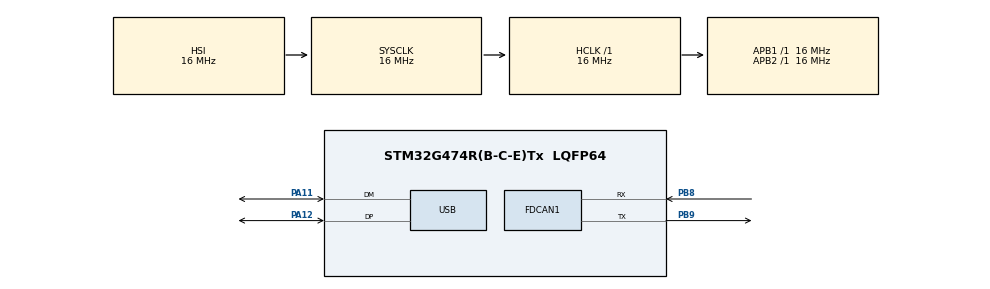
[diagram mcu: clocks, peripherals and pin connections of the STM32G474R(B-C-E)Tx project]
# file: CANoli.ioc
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FDCAN1.CalculateBaudRateNominal=333333
FDCAN1.CalculateTimeBitNominal=3000
FDCAN1.CalculateTimeQuantumNominal=1000.0
Mcu.Family=STM32G4
Mcu.Name=STM32G474R(B-C-E)Tx
Mcu.Package=LQFP64
NVIC.FDCAN1_IT0_IRQn=true\:0\:0\:false\:false\:true\:true\:true\:true
NVIC.FDCAN1_IT1_IRQn=true\:0\:0\:false\:false\:true\:true\:true\:true
NVIC.PriorityGroup=NVIC_PRIORITYGROUP_4
NVIC.USB_HP_IRQn=true\:0\:0\:false\:false\:true\:true\:true\:true
NVIC.USB_LP_IRQn=true\:0\:0\:false\:false\:true\:true\:true\:true
PA11.Mode=Device
PA11.Signal=USB_DM
PA12.Mode=Device
PA12.Signal=USB_DP
PB8-BOOT0.Mode=FDCAN_Activate
PB8-BOOT0.Signal=FDCAN1_RX
PB9.Mode=FDCAN_Activate
PB9.Signal=FDCAN1_TX
ProjectManager.HeapSize=0x200
ProjectManager.StackSize=0x400
ProjectManager.TargetToolchain=CMake
RCC.AHBFreq_Value=16000000
RCC.APB1Freq_Value=16000000
RCC.APB1TimFreq_Value=16000000
RCC.APB2Freq_Value=16000000
RCC.APB2TimFreq_Value=16000000
RCC.CortexFreq_Value=16000000
RCC.EXTERNAL_CLOCK_VALUE=12288000
RCC.HCLKFreq_Value=16000000
RCC.HSE_VALUE=8000000
RCC.HSI48_VALUE=48000000
RCC.HSI_VALUE=16000000
RCC.LSE_VALUE=32768
RCC.PLLN=12
RCC.PLLQ=RCC_PLLQ_DIV4
RCC.SYSCLKFreq_VALUE=16000000
RCC.USBFreq_Value=48000000
RCC.VCOOutputFreq_Value=192000000
VP_SYS_VS_DBSignals.Mode=DisableDeadBatterySignals
board=custom

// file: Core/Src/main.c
/* USER CODE BEGIN Header */
/**
  ******************************************************************************
  * @file           : main.c
  * @brief          : Main program body
  ******************************************************************************
  * @attention
  *
  * Copyright (c) 2026 STMicroelectronics.
  * All rights reserved.
  *
  * This software is licensed under terms that can be found in the LICENSE file
  * in the root directory of this software component.
  * If no LICENSE file comes with this software, it is provided AS-IS.
  *
  ******************************************************************************
  */
/* USER CODE END Header */
#include "main.h"

/* USER CODE BEGIN Includes */
#include "rosjam.h"
#include "tusb_config.h"
#include "tusb.h"

/* USER CODE END Includes */

FDCAN_HandleTypeDef hfdcan1;

PCD_HandleTypeDef hpcd_USB_FS;

void SystemClock_Config(void);
static void MX_GPIO_Init(void);
static void MX_FDCAN1_Init(void);
static void MX_USB_PCD_Init(void);

int main(void)
{

  /* MCU Configuration--------------------------------------------------------*/

  /* Reset of all peripherals, Initializes the Flash interface and the Systick. */
  HAL_Init();

  /* Configure the system clock */
  SystemClock_Config();

  /* Initialize all configured peripherals */
  MX_GPIO_Init();
  MX_FDCAN1_Init();
  MX_USB_PCD_Init();

  /* Infinite loop */
  /* USER CODE BEGIN WHILE */
  while (!tud_cdc_ready())
  {
    process_simple();
    /* USER CODE END WHILE */

  }
}

void SystemClock_Config(void)
{
  RCC_OscInitTypeDef RCC_OscInitStruct = {0};
  RCC_ClkInitTypeDef RCC_ClkInitStruct = {0};

  /** Configure the main internal regulator output voltage
  */
  HAL_PWREx_ControlVoltageScaling(PWR_REGULATOR_VOLTAGE_SCALE1);

  /** Initializes the RCC Oscillators according to the specified parameters
  * in the RCC_OscInitTypeDef structure.
  */
  RCC_OscInitStruct.OscillatorType = RCC_OSCILLATORTYPE_HSI;
  RCC_OscInitStruct.HSIState = RCC_HSI_ON;
  RCC_OscInitStruct.HSICalibrationValue = RCC_HSICALIBRATION_DEFAULT;
  RCC_OscInitStruct.PLL.PLLState = RCC_PLL_ON;
  RCC_OscInitStruct.PLL.PLLSource = RCC_PLLSOURCE_HSI;
  RCC_OscInitStruct.PLL.PLLM = RCC_PLLM_DIV1;
  RCC_OscInitStruct.PLL.PLLN = 12;
  RCC_OscInitStruct.PLL.PLLP = RCC_PLLP_DIV2;
  RCC_OscInitStruct.PLL.PLLQ = RCC_PLLQ_DIV4;
  RCC_OscInitStruct.PLL.PLLR = RCC_PLLR_DIV2;
  if (HAL_RCC_OscConfig(&RCC_OscInitStruct) != HAL_OK)
  {
    Error_Handler();
  }

  /** Initializes the CPU, AHB and APB buses clocks
  */
  RCC_ClkInitStruct.ClockType = RCC_CLOCKTYPE_HCLK|RCC_CLOCKTYPE_SYSCLK
                              |RCC_CLOCKTYPE_PCLK1|RCC_CLOCKTYPE_PCLK2;
  RCC_ClkInitStruct.SYSCLKSource = RCC_SYSCLKSOURCE_HSI;
  RCC_ClkInitStruct.AHBCLKDivider = RCC_SYSCLK_DIV1;
  RCC_ClkInitStruct.APB1CLKDivider = RCC_HCLK_DIV1;
  RCC_ClkInitStruct.APB2CLKDivider = RCC_HCLK_DIV1;

  if (HAL_RCC_ClockConfig(&RCC_ClkInitStruct, FLASH_LATENCY_0) != HAL_OK)
  {
    Error_Handler();
  }
}

static void MX_FDCAN1_Init(void)
{

  hfdcan1.Instance = FDCAN1;
  hfdcan1.Init.ClockDivider = FDCAN_CLOCK_DIV1;
  hfdcan1.Init.FrameFormat = FDCAN_FRAME_CLASSIC;
  hfdcan1.Init.Mode = FDCAN_MODE_NORMAL;
  hfdcan1.Init.AutoRetransmission = DISABLE;
  hfdcan1.Init.TransmitPause = DISABLE;
  hfdcan1.Init.ProtocolException = DISABLE;
  hfdcan1.Init.NominalPrescaler = 16;
  hfdcan1.Init.NominalSyncJumpWidth = 1;
  hfdcan1.Init.NominalTimeSeg1 = 1;
  hfdcan1.Init.NominalTimeSeg2 = 1;
  hfdcan1.Init.DataPrescaler = 1;
  hfdcan1.Init.DataSyncJumpWidth = 1;
  hfdcan1.Init.DataTimeSeg1 = 1;
  hfdcan1.Init.DataTimeSeg2 = 1;
  hfdcan1.Init.StdFiltersNbr = 0;
  hfdcan1.Init.ExtFiltersNbr = 0;
  hfdcan1.Init.TxFifoQueueMode = FDCAN_TX_FIFO_OPERATION;
  if (HAL_FDCAN_Init(&hfdcan1) != HAL_OK)
  {
    Error_Handler();
  }

}

static void MX_USB_PCD_Init(void)
{

  hpcd_USB_FS.Instance = USB;
  hpcd_USB_FS.Init.dev_endpoints = 8;
  hpcd_USB_FS.Init.speed = PCD_SPEED_FULL;
  hpcd_USB_FS.Init.phy_itface = PCD_PHY_EMBEDDED;
  hpcd_USB_FS.Init.Sof_enable = DISABLE;
  hpcd_USB_FS.Init.low_power_enable = DISABLE;
  hpcd_USB_FS.Init.lpm_enable = DISABLE;
  hpcd_USB_FS.Init.battery_charging_enable = DISABLE;
  if (HAL_PCD_Init(&hpcd_USB_FS) != HAL_OK)
  {
    Error_Handler();
  }

}

static void MX_GPIO_Init(void)
{

  /* GPIO Ports Clock Enable */
  __HAL_RCC_GPIOA_CLK_ENABLE();
  __HAL_RCC_GPIOB_CLK_ENABLE();

}

void Error_Handler(void)
{
  __disable_irq();
  while (1)
  {
  }
}
